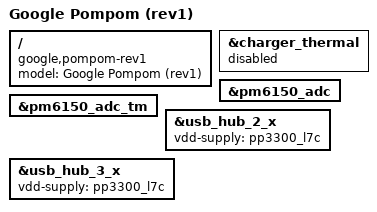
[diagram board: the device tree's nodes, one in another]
// SPDX-License-Identifier: (GPL-2.0+ OR MIT)
/*
 * Google Pompom board device tree source
 *
 * Copyright 2020 Google LLC.
 */

/dts-v1/;

#include "sc7180-trogdor-pompom.dtsi"

/delete-node/ &keyboard_controller;
#include <arm/cros-ec-keyboard.dtsi>

/ {
	model = "Google Pompom (rev1)";
	compatible = "google,pompom-rev1", "qcom,sc7180";
};

/*
 * Pompom rev1 is stuffed with a 47k NTC as charger thermistor which currently
 * is not supported by the PM6150 ADC driver. Disable the charger thermal zone
 * to avoid using bogus temperature values.
 */
&charger_thermal {
	status = "disabled";
};

&pm6150_adc {
	/delete-node/ charger-thermistor@4f;
};

&pm6150_adc_tm {
	/delete-node/ charger-thermistor@0;
};

&usb_hub_2_x {
	 vdd-supply = <&pp3300_l7c>;
};

&usb_hub_3_x {
	 vdd-supply = <&pp3300_l7c>;
};
